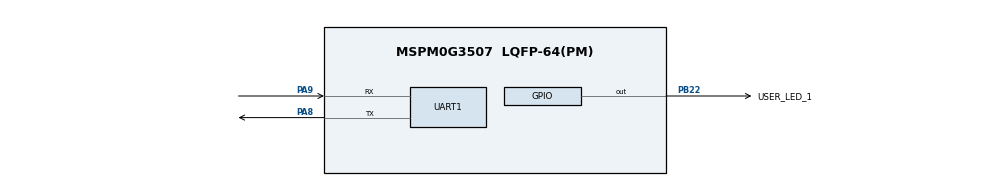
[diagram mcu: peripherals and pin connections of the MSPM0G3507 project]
/**
 * ECHO platform configuration.
 * 80 MHz MCLK, 1 MHz TIMG12 timebase, and Tianmengxing PB22 LED.
 */
//@cliArgs --device "MSPM0G350X" --package "LQFP-64(PM)" --part "Default"
//@v2CliArgs --device "MSPM0G3507" --package "LQFP-64(PM)"
// @cliArgs --board /ti/boards/LP_MSPM0G3507 --rtos freertos

const ProjectConfig = scripting.addModule("/ti/project_config/ProjectConfig");
const GPIO   = scripting.addModule("/ti/driverlib/GPIO", {}, false);
const GPIO1  = GPIO.addInstance();
const SYSCTL = scripting.addModule("/ti/driverlib/SYSCTL");
const TIMER  = scripting.addModule("/ti/driverlib/TIMER", {}, false);
const TIMER1 = TIMER.addInstance();

ProjectConfig.genDisable = true;

const pllClk1Divider = system.clockTree["PLL_CLK1_DIV"];
pllClk1Divider.divideValue = 4;

const pllClk2xDivider = system.clockTree["PLL_CLK2X_DIV"];
pllClk2xDivider.divideValue = 4;

const pllPDivider = system.clockTree["PLL_PDIV"];
pllPDivider.divideValue = 2;

const ulpClkDivider = system.clockTree["UDIV"];
ulpClkDivider.divideValue = 2;

const pllQDivider = system.clockTree["PLL_QDIV"];
pllQDivider.multiplyValue = 10;

const hsclkMux = system.clockTree["HSCLKMUX"];
hsclkMux.inputSelect = "HSCLKMUX_SYSPLL2X";

const mfclkGate = system.clockTree["MFCLKGATE"];
mfclkGate.enable = true;

GPIO1.$name                          = "GPIO_LEDS";
GPIO1.associatedPins[0].$name        = "USER_LED_1";
GPIO1.associatedPins[0].assignedPin  = "22";
GPIO1.associatedPins[0].initialValue = "SET";
GPIO1.associatedPins[0].internalResistor = "PULL_DOWN";
GPIO1.associatedPins[0].pin.$assign  = "PB22";

const Board = scripting.addModule("/ti/driverlib/Board", {}, false);
SYSCTL.MCLKSource            = "HSCLK";
SYSCTL.SYSPLL_CLK1En         = true;
SYSCTL.SYSPLL_CLK2XEn        = true;
SYSCTL.SYSPLL_CLK2XDiv       = 1;
SYSCTL.HSCLKSource           = "SYSPLLCLK2X";
SYSCTL.validateClkStatus     = true;
SYSCTL.SYSPLL_Qdiv           = 5;
SYSCTL.MFCLKEn               = true;
SYSCTL.forceDefaultClkConfig = true;
SYSCTL.clockTreeEn           = true;

TIMER1.$name              = "TIMEBASE";
TIMER1.timerClkSrc        = "MFCLK";
TIMER1.timerClkDiv        = 4;
TIMER1.timerClkPrescale   = 1;
TIMER1.timerMode          = "PERIODIC_UP";
TIMER1.timerPeriod        = "4294.967296 s";
TIMER1.timerStartTimer    = false;
TIMER1.peripheral.$assign = "TIMG12";
TIMER1.interrupts         = [];
const UART   = scripting.addModule("/ti/driverlib/UART", {}, false);
const UART1  = UART.addInstance();

const ECHO_DEBUG_UART_BAUD = 460800;

UART1.$name = "DEBUG_UART";
UART1.profile = "CONFIG_PROFILE_1";
UART1.peripheral.$assign = "UART1";
UART1.targetBaudRate = ECHO_DEBUG_UART_BAUD;
UART1.enableInternalLoopback = false;
UART1.enabledInterrupts = ["DMA_DONE_TX", "EOT_DONE", "RX"];
UART1.enableFIFO = true;
UART1.txFifoThreshold = "DL_UART_TX_FIFO_LEVEL_ONE_ENTRY";
UART1.enabledDMATXTriggers = "DL_UART_DMA_INTERRUPT_TX";
UART1.enableDMATX = true;
UART1.peripheral.rxPin.$assign = "PA9";
UART1.peripheral.txPin.$assign = "PA8";
UART1.DMA_CHANNEL_TX.$name = "DEBUG_UART_TX_DMA";
UART1.DMA_CHANNEL_TX.peripheral.$assign = "DMA_CH3";
UART1.DMA_CHANNEL_TX.addressMode = "b2f";
UART1.DMA_CHANNEL_TX.srcIncDec = "INCREMENT";
UART1.DMA_CHANNEL_TX.dstLength = "BYTE";
UART1.DMA_CHANNEL_TX.srcLength = "BYTE";
